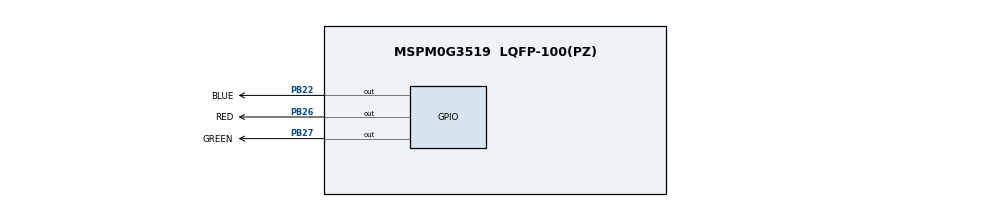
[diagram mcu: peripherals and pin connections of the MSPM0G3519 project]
//@cliArgs --device "MSPM0G351X" --package "LQFP-100(PZ)" --part "Default"
//@v2CliArgs --device "MSPM0G3519" --package "LQFP-100(PZ)"
// @cliArgs --board /ti/boards/LP_MSPM0G3519 --rtos nortos

/**
 * Import the modules used in this configuration.
 */
const GPIO  = scripting.addModule("/ti/driverlib/GPIO", {}, false);
const GPIO1 = GPIO.addInstance();

/**
 * Write custom configuration values to the imported modules.
 */
GPIO1.$name                          = "GPIO_LED";
GPIO1.associatedPins.create(4);
GPIO1.associatedPins[0].$name        = "BLUE";
GPIO1.associatedPins[0].pin.$assign  = "PB22";
GPIO1.associatedPins[1].$name        = "RED";
GPIO1.associatedPins[1].pin.$assign  = "PB26";
GPIO1.associatedPins[2].$name        = "GREEN";
GPIO1.associatedPins[2].pin.$assign  = "PB27";
GPIO1.associatedPins[3].$name        = "PIN_0";
GPIO1.associatedPins[3].assignedPort = "PORTA";
GPIO1.associatedPins[3].direction    = "INPUT";

const Board = scripting.addModule("/ti/driverlib/Board", {}, false);

const SYSCTL = scripting.addModule("/ti/driverlib/SYSCTL", {}, false);

const ProjectConfig              = scripting.addModule("/ti/project_config/ProjectConfig", {}, false);
ProjectConfig.migrationCondition = true;
